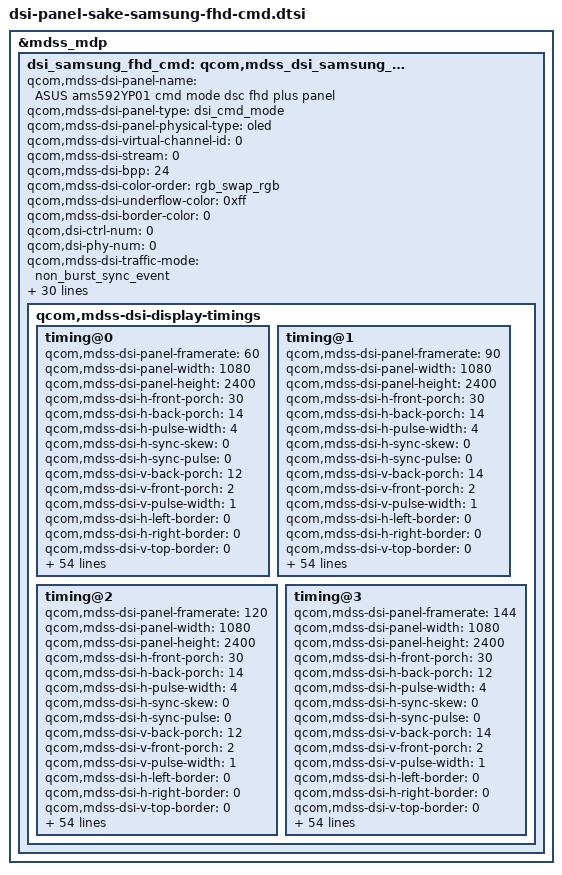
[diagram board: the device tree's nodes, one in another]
&mdss_mdp {
	dsi_samsung_fhd_cmd: qcom,mdss_dsi_samsung_fhd_cmd {
		qcom,mdss-dsi-panel-name = "ASUS ams592YP01 cmd mode dsc fhd plus panel";
		qcom,mdss-dsi-panel-type = "dsi_cmd_mode";
		qcom,mdss-dsi-panel-physical-type = "oled";
		qcom,mdss-dsi-virtual-channel-id = <0>;
		qcom,mdss-dsi-stream = <0>;
		qcom,mdss-dsi-bpp = <24>;
		qcom,mdss-dsi-color-order = "rgb_swap_rgb";
		qcom,mdss-dsi-underflow-color = <0xff>;
		qcom,mdss-dsi-border-color = <0>;

		qcom,dsi-ctrl-num = <0>;
		qcom,dsi-phy-num = <0>;

		qcom,mdss-dsi-traffic-mode = "non_burst_sync_event";
		qcom,mdss-dsi-lane-map = "lane_map_0123";
		qcom,mdss-dsi-bllp-eof-power-mode;
		qcom,mdss-dsi-bllp-power-mode;
		qcom,mdss-dsi-lane-0-state;
		qcom,mdss-dsi-lane-1-state;
		qcom,mdss-dsi-lane-2-state;
		qcom,mdss-dsi-lane-3-state;
		qcom,mdss-dsi-dma-trigger = "trigger_sw";
		qcom,mdss-dsi-mdp-trigger = "none";
		qcom,mdss-dsi-reset-sequence = <0 1>,<0 1>, <1 10>;
		qcom,mdss-dsi-te-pin-select = <1>;
		qcom,mdss-dsi-wr-mem-start = <0x2c>;
		qcom,mdss-dsi-wr-mem-continue = <0x3c>;
		qcom,mdss-dsi-te-dcs-command = <1>;
		qcom,mdss-dsi-te-check-enable;
		qcom,mdss-dsi-te-using-te-pin;
		qcom,mdss-pan-physical-width-dimension = <62>;
		qcom,mdss-pan-physical-height-dimension = <137>;
		qcom,mdss-dsi-panel-hdr-enabled;
		qcom,mdss-dsi-panel-hdr-color-primaries = <15635 16450 34000
			16000 13250 34500 7500 3000>;
		qcom,mdss-dsi-panel-peak-brightness = <4500000>;
		qcom,mdss-dsi-panel-blackness-level = <5>;

		qcom,mdss-dsi-panel-vendor-id = "AMS592YP01";
		qcom,mdss-dsi-bl-inverted-dbv;
		qcom,dynamic-mode-switch-enabled;
		qcom,dynamic-mode-switch-type = "dynamic-resolution-switch-immediate";

		qcom,fod-dim-lut = <
			/* brightness, alpha */
			4	233
			8	229
			12	225
			16	221
			20	218
			24	215
			28	213
			32	209
			36	207
			40	205
			44	203
			48	200
			52	200
			56	199
			60	196
			64	194
			68	192
			72	191
			76	189
			80	187
			84	186
			88	184
			92	182
			96	182
			100	181
			104	180
			108	178
			112	178
			116	176
			120	176
			124	176
			128	174
			132	172
			136	172
			140	171
			144	169
			148	168
			152	168
			156	166
			160	165
			164	165
			168	163
			172	163
			176	161
			180	160
			184	159
			188	159
			192	158
			196	156
			200	156
			234	151
			266	144
			299	138
			332	138
			365	128
			398	124
			431	117
			464	113
			497	108
			529	104
			562	99
			595	96
			628	92
			661	89
			694	86
			727	82
			760	79
			792	76
			825	74
			858	71
			891	70
			924	65
			957	60
			990	58
			1023	53
		>;

		qcom,mdss-dsi-display-timings {
			timing@0{
				qcom,mdss-dsi-panel-framerate = <60>;
				qcom,mdss-dsi-panel-width = <1080>;
				qcom,mdss-dsi-panel-height = <2400>;
				qcom,mdss-dsi-h-front-porch = <30>;
				qcom,mdss-dsi-h-back-porch = <14>;
				qcom,mdss-dsi-h-pulse-width = <4>;
				qcom,mdss-dsi-h-sync-skew = <0>;
				qcom,mdss-dsi-h-sync-pulse = <0>;
				qcom,mdss-dsi-v-back-porch = <12>;
				qcom,mdss-dsi-v-front-porch = <2>;
				qcom,mdss-dsi-v-pulse-width = <1>;
				qcom,mdss-dsi-h-left-border = <0>;
				qcom,mdss-dsi-h-right-border = <0>;
				qcom,mdss-dsi-v-top-border = <0>;
				qcom,mdss-dsi-v-bottom-border = <0>;
				qcom,mdss-dsi-panel-jitter = <0x05 0xa>;
				qcom,mdss-dsi-panel-clockrate = <1100000000>;

				qcom,default-topology-index = <0>;
				qcom,display-topology = <0x02 0x02 0x01>;
				qcom,mdss-dsi-panel-phy-timings = [00 13 04 04 13 1f 04 04 04 02 04 00 10 09];

				qcom,mdss-dsi-on-command = [05 01 00 00 0a 00 02 11 00 39 01 00 00 00 00 81 9e 11 00 00 89 30 80 09 60 04 38 00 28 02 1c 02 1c 02 00 02 0e 00 20 03 dd 00 07 00 0c 02 77 02 8b 18 00 10 f0 03 0c 20 00 06 0b 0b 33 0e 1c 2a 38 46 54 62 69 70 77 79 7b 7d 7e 01 02 01 00 09 40 09 be 19 fc 19 fa 19 f8 1a 38 1a 78 1a b6 2a f6 2b 34 2b 74 3b 74 6b f4 00 00 00 00 00 00 00 00 00 00 00 00 00 00 00 00 00 00 00 00 00 00 00 00 00 00 00 00 00 00 00 00 00 00 00 00 00 00 00 00 15 01 00 00 00 00 02 c2 14 15 01 00 00 00 00 02 9d 01 15 01 00 00 0a 00 02 35 00 39 01 00 00 00 00 05 2a 00 00 04 37 39 01 00 00 00 00 05 2b 00 00 09 5f 39 01 00 00 00 00 03 f0 5a 5a 39 01 00 00 00 00 03 b0 27 f2 15 01 00 00 00 00 02 f2 00 39 01 00 00 00 00 03 f0 a5 a5 39 01 00 00 00 00 03 f0 5a 5a 39 01 00 00 00 00 03 fc 5a 5a 15 01 00 00 00 00 02 c5 00 39 01 00 00 00 00 03 f0 a5 a5 39 01 00 00 00 00 03 fc a5 a5 39 01 00 00 00 00 03 f0 5a 5a 39 01 00 00 00 00 03 60 08 00 15 01 00 00 00 00 02 f7 0f 39 01 00 00 00 00 03 f0 a5 a5 39 01 00 00 00 00 03 f0 5a 5a 39 01 00 00 00 00 03 b0 09 f2 39 01 00 00 00 00 03 f2 26 f8 39 01 00 00 00 00 03 f0 a5 a5 39 01 00 00 00 00 03 f0 5a 5a 39 01 00 00 00 00 03 b0 2e f2 15 01 00 00 00 00 02 f2 55 15 01 00 00 00 00 02 f7 0f 39 01 00 00 00 00 03 f0 a5 a5 39 01 00 00 00 00 03 f0 5a 5a 39 01 00 00 00 00 03 b0 91 63 15 01 00 00 00 00 02 63 14 15 01 00 00 00 00 02 53 20 39 01 00 00 00 00 03 51 00 00 39 01 00 00 00 00 03 f0 a5 a5 15 01 00 00 00 00 02 53 28 15 01 00 00 00 00 02 55 00 05 01 00 00 00 00 02 29 00 39 01 00 00 00 00 03 f0 5a 5a 39 01 00 00 00 00 03 60 00 00 15 01 00 00 00 00 02 f7 0f 39 01 00 00 00 00 03 f0 a5 a5];

				qcom,mdss-dsi-off-command = [
					05 01 00 00 0A 00 02 28 00
					05 01 00 00 78 00 02 10 00
				];

				qcom,mdss-dsi-timing-switch-command = <0x39010000 0x3f0 0x5a5a3901 0x00 0x3fc5a5a 0x15010000 0x2c5 0x390100 0x03 0xf0a5a539 0x1000000 0x3fca5 0xa5390100 0x03 0xf05a5a39 0x1000000 0x36008 0x150100 0x02 0xf70f3901 0x00 0x3f0a5a5 0x39010000 0x3f0 0x5a5a3901 0x00 0x3b009f2 0x39010000 0x3f2 0x26f83901 0x00 0x3f0a5a5 0x39010000 0x3f0 0x5a5a3901 0x00 0x3600000 0x15010000 0x2f7 0xf390100 0x03 0xf0a5a515 0x1000000 0x25500>;

				qcom,mdss-dsi-fod-hbm-on-command = [
					// ELVSS DIM OFF & DLY OFF
					39 01 00 00 1C 00 03 F0 5A 5A
					39 01 00 00 00 00 03 B0 91 63
					15 01 00 00 00 00 02 63 50
					39 01 00 00 00 00 03 F0 A5 A5
					// HBM ON
					15 01 00 00 00 00 02 53 E0
					39 01 00 00 00 00 03 51 07 1C
				];

				qcom,mdss-dsi-fod-hbm-off-command = [
					// HBM OFF
					15 01 00 00 00 00 02 53 20
					// ELVSS DIM ON & DLY ON
					39 01 00 00 00 00 03 F0 5A 5A
					39 01 00 00 00 00 03 B0 91 63
					15 01 00 00 00 00 02 63 50
					39 01 00 00 00 00 03 F0 A5 A5
				];

				qcom,mdss-dsi-lp1-command = [
					//5.4 Frequency Change  60-120Hz
					39 01 00 00 00 00 03 F0 5A 5A
					39 01 00 00 00 00 03 60 08 00
					15 01 00 00 00 00 02 F7 0F
					39 01 00 00 00 00 03 F0 A5 A5
					05 01 00 00 10 00 02 28 00
				];

				qcom,mdss-dsi-nolp-command = [
					//4.2 AOD Mode OFF Setting
					39 01 00 00 00 00 03 F0 5A 5A
					15 01 00 00 00 00 02 53 20
					15 01 00 00 00 00 02 91 02
					39 01 00 00 00 00 03 F0 A5 A5
					05 01 00 00 00 00 02 29 00
					//5.4 Frequency Change  120-60Hz
					39 01 00 00 00 00 03 F0 5A 5A
					39 01 00 00 00 00 03 60 00 00
					15 01 00 00 00 00 02 F7 0F
					39 01 00 00 00 00 03 F0 A5 A5
				];

				qcom,mdss-dsi-aod-high-command = [
					// 24 for 40 nit
					39 01 00 00 00 00 03 F0 5A 5A
					15 01 00 00 00 00 02 91 01
					15 01 00 00 10 00 02 53 24
					39 01 00 00 00 00 03 F0 A5 A5
					05 01 00 00 00 00 02 29 00
				];

				qcom,mdss-dsi-aod-low-command = [
					// 25 for Low Mode
					39 01 00 00 00 00 03 F0 5A 5A
					15 01 00 00 00 00 02 91 01
					15 01 00 00 10 00 02 53 25
					39 01 00 00 00 00 03 F0 A5 A5
					05 01 00 00 00 00 02 29 00
				];

				qcom,mdss-dsi-aod-other-command = [
					05 01 00 00 00 00 02 29 00
				];

				qcom,mdss-dsi-aod-off-command = [
					05 01 00 00 10 00 02 28 00
				];

				qcom,mdss-dsi-on-command-state = "dsi_lp_mode";
				qcom,mdss-dsi-off-command-state = "dsi_hs_mode";
				qcom,mdss-dsi-timing-switch-command-state = "dsi_hs_mode";
				qcom,mdss-dsi-fod-hbm-on-command-state = "dsi_hs_mode";
				qcom,mdss-dsi-fod-hbm-off-command-state = "dsi_hs_mode";
				qcom,mdss-dsi-lp1-command-state = "dsi_hs_mode";
				qcom,mdss-dsi-nolp-command-state = "dsi_hs_mode";
				qcom,mdss-dsi-aod-high-command-state = "dsi_hs_mode";
				qcom,mdss-dsi-aod-low-command-state = "dsi_hs_mode";
				qcom,mdss-dsi-aod-other-command-state = "dsi_hs_mode";
				qcom,mdss-dsi-aod-off-command-state = "dsi_hs_mode";


				/* DSC */
				qcom,compression-mode = "dsc";
				qcom,mdss-dsc-slice-height = <40>;
				qcom,mdss-dsc-slice-width = <540>;
				qcom,mdss-dsc-slice-per-pkt = <1>;
				qcom,mdss-dsc-bit-per-component = <8>;
				qcom,mdss-dsc-bit-per-pixel = <8>;
				qcom,mdss-dsc-block-prediction-enable;
			};

			timing@1{
				qcom,mdss-dsi-panel-framerate = <90>;
				qcom,mdss-dsi-panel-width = <1080>;
				qcom,mdss-dsi-panel-height = <2400>;
				qcom,mdss-dsi-h-front-porch = <30>;
				qcom,mdss-dsi-h-back-porch = <14>;
				qcom,mdss-dsi-h-pulse-width = <4>;
				qcom,mdss-dsi-h-sync-skew = <0>;
				qcom,mdss-dsi-h-sync-pulse = <0>;
				qcom,mdss-dsi-v-back-porch = <14>;
				qcom,mdss-dsi-v-front-porch = <2>;
				qcom,mdss-dsi-v-pulse-width = <1>;
				qcom,mdss-dsi-h-left-border = <0>;
				qcom,mdss-dsi-h-right-border = <0>;
				qcom,mdss-dsi-v-top-border = <0>;
				qcom,mdss-dsi-v-bottom-border = <0>;
				qcom,mdss-dsi-panel-jitter = <0x05 0xa>;
				qcom,mdss-dsi-panel-clockrate = <1100000000>;

				qcom,default-topology-index = <0>;
				qcom,display-topology = <0x02 0x02 0x01>;
				qcom,mdss-dsi-panel-phy-timings = [00 13 04 04 13 1f 04 04 04 02 04 00 10 09];

				qcom,mdss-dsi-on-command = <0x5010000 0xa000211 0x390100 0x81 0x9e110000 0x89308009 0x60043800 0x28021c02 0x1c020002 0xe002003 0xdd000700 0xc027702 0x8b180010 0xf0030c20 0x60b0b 0x330e1c2a 0x38465462 0x69707779 0x7b7d7e01 0x2010009 0x4009be19 0xfc19fa19 0xf81a381a 0x781ab62a 0xf62b342b 0x743b746b 0xf4000000 0x00 0x00 0x00 0x00 0x00 0x00 0x00 0x00 0x00 0x150100 0x02 0xc2141501 0x00 0x29d0115 0x100000a 0x23500 0x39010000 0x52a 0x437 0x39010000 0x52b 0x95f 0x39010000 0x3f0 0x5a5a3901 0x00 0x3b027f2 0x15010000 0x2f2 0x390100 0x03 0xf0a5a539 0x1000000 0x3f05a 0x5a390100 0x03 0xfc5a5a15 0x1000000 0x2c500 0x39010000 0x3f0 0xa5a53901 0x00 0x3fca5a5 0x39010000 0x3f0 0x5a5a3901 0x00 0x3600800 0x15010000 0x2f7 0xf390100 0x03 0xf0a5a539 0x1000000 0x3f05a 0x5a390100 0x03 0xb009f239 0x1000000 0x3f226 0xf8390100 0x03 0xf0a5a539 0x1000000 0x3f05a 0x5a390100 0x03 0xb02ef215 0x1000000 0x2f255 0x15010000 0x2f7 0xf390100 0x03 0xf0a5a539 0x1000000 0x3f05a 0x5a390100 0x03 0xb0916315 0x1000000 0x26314 0x15010000 0x253 0x20390100 0x03 0x51000039 0x1000000 0x3f0a5 0xa5150100 0x02 0x53281501 0x00 0x2550005 0x1000000 0x22900 0x39010000 0x3f0 0x5a5a3901 0x00 0x3b009f2 0x39010000 0x3f2 0x33a83901 0x00 0x3f0a5a5>;

				qcom,mdss-dsi-off-command = [
					05 01 00 00 0A 00 02 28 00
					05 01 00 00 78 00 02 10 00
				];

				qcom,mdss-dsi-timing-switch-command = [39 01 00 00 00 00 03 f0 5a 5a 39 01 00 00 00 00 03 fc 5a 5a 15 01 00 00 00 00 02 c5 00 39 01 00 00 00 00 03 f0 a5 a5 39 01 00 00 00 00 03 fc a5 a5 39 01 00 00 00 00 03 f0 5a 5a 39 01 00 00 00 00 03 60 08 00 15 01 00 00 00 00 02 f7 0f 39 01 00 00 00 00 03 f0 a5 a5 39 01 00 00 00 00 03 f0 5a 5a 39 01 00 00 00 00 03 b0 09 f2 39 01 00 00 00 00 03 f2 33 a8 39 01 00 00 00 00 03 f0 a5 a5 15 01 00 00 00 00 02 55 00];

				qcom,mdss-dsi-fod-hbm-on-command = [
					// ELVSS DIM OFF & DLY OFF
					39 01 00 00 00 00 03 F0 5A 5A
					39 01 00 00 00 00 03 B0 91 63
					15 01 00 00 00 00 02 63 50
					39 01 00 00 00 00 03 F0 A5 A5
					// HBM ON
					15 01 00 00 00 00 02 53 E0
					39 01 00 00 00 00 03 51 07 1C
				];

				qcom,mdss-dsi-fod-hbm-off-command = [
					// HBM OFF
					15 01 00 00 00 00 02 53 20
					// ELVSS DIM ON & DLY ON
					39 01 00 00 00 00 03 F0 5A 5A
					39 01 00 00 00 00 03 B0 91 63
					15 01 00 00 00 00 02 63 50
					39 01 00 00 00 00 03 F0 A5 A5
				];

				qcom,mdss-dsi-lp1-command = [
					//7 Frequency Setting  90-120Hz
					39 01 00 00 00 00 03 F0 5A 5A
					39 01 00 00 00 00 03 B0 09 F2
					39 01 00 00 00 00 03 F2 26 F8
					39 01 00 00 00 00 03 F0 A5 A5
					05 01 00 00 10 00 02 28 00
				];

				qcom,mdss-dsi-nolp-command = [
					//4.2 AOD Mode OFF Setting
					39 01 00 00 00 00 03 F0 5A 5A
					15 01 00 00 00 00 02 53 20
					15 01 00 00 00 00 02 91 02
					39 01 00 00 00 00 03 F0 A5 A5
					05 01 00 00 00 00 02 29 00
					//5.4 Frequency Change  120-90Hz
					39 01 00 00 00 00 03 F0 5A 5A
					39 01 00 00 00 00 03 B0 09 F2
					39 01 00 00 00 00 03 F2 33 A8
					39 01 00 00 00 00 03 F0 A5 A5
				];

				qcom,mdss-dsi-aod-high-command = [
					// 24 for 40 nit
					39 01 00 00 00 00 03 F0 5A 5A
					15 01 00 00 00 00 02 91 01
					15 01 00 00 10 00 02 53 24
					39 01 00 00 00 00 03 F0 A5 A5
					05 01 00 00 00 00 02 29 00
				];

				qcom,mdss-dsi-aod-low-command = [
					// 25 for Low Mode
					39 01 00 00 00 00 03 F0 5A 5A
					15 01 00 00 00 00 02 91 01
					15 01 00 00 10 00 02 53 25
					39 01 00 00 00 00 03 F0 A5 A5
					05 01 00 00 00 00 02 29 00
				];

				qcom,mdss-dsi-aod-other-command = [
					05 01 00 00 00 00 02 29 00
				];

				qcom,mdss-dsi-aod-off-command = [
					05 01 00 00 10 00 02 28 00
				];

				qcom,mdss-dsi-on-command-state = "dsi_lp_mode";
				qcom,mdss-dsi-off-command-state = "dsi_hs_mode";
				qcom,mdss-dsi-timing-switch-command-state = "dsi_hs_mode";
				qcom,mdss-dsi-fod-hbm-on-command-state = "dsi_hs_mode";
				qcom,mdss-dsi-fod-hbm-off-command-state = "dsi_hs_mode";
				qcom,mdss-dsi-lp1-command-state = "dsi_hs_mode";
				qcom,mdss-dsi-nolp-command-state = "dsi_hs_mode";
				qcom,mdss-dsi-aod-high-command-state = "dsi_hs_mode";
				qcom,mdss-dsi-aod-low-command-state = "dsi_hs_mode";
				qcom,mdss-dsi-aod-other-command-state = "dsi_hs_mode";
				qcom,mdss-dsi-aod-off-command-state = "dsi_hs_mode";

				/* DSC */
				qcom,compression-mode = "dsc";
				qcom,mdss-dsc-slice-height = <40>;
				qcom,mdss-dsc-slice-width = <540>;
				qcom,mdss-dsc-slice-per-pkt = <1>;
				qcom,mdss-dsc-bit-per-component = <8>;
				qcom,mdss-dsc-bit-per-pixel = <8>;
				qcom,mdss-dsc-block-prediction-enable;
			};

			timing@2{
				qcom,mdss-dsi-panel-framerate = <120>;
				qcom,mdss-dsi-panel-width = <1080>;
				qcom,mdss-dsi-panel-height = <2400>;
				qcom,mdss-dsi-h-front-porch = <30>;
				qcom,mdss-dsi-h-back-porch = <14>;
				qcom,mdss-dsi-h-pulse-width = <4>;
				qcom,mdss-dsi-h-sync-skew = <0>;
				qcom,mdss-dsi-h-sync-pulse = <0>;
				qcom,mdss-dsi-v-back-porch = <12>;
				qcom,mdss-dsi-v-front-porch = <2>;
				qcom,mdss-dsi-v-pulse-width = <1>;
				qcom,mdss-dsi-h-left-border = <0>;
				qcom,mdss-dsi-h-right-border = <0>;
				qcom,mdss-dsi-v-top-border = <0>;
				qcom,mdss-dsi-v-bottom-border = <0>;
				qcom,mdss-dsi-panel-jitter = <0x05 0xa>;
				qcom,mdss-dsi-panel-clockrate = <1100000000>;

				qcom,default-topology-index = <0>;
				qcom,display-topology = <0x02 0x02 0x01>;
				qcom,mdss-dsi-panel-phy-timings = [00 13 04 04 13 1f 04 04 04 02 04 00 10 09];

				qcom,mdss-dsi-on-command = <0x5010000 0xa000211 0x390100 0x81 0x9e110000 0x89308009 0x60043800 0x28021c02 0x1c020002 0xe002003 0xdd000700 0xc027702 0x8b180010 0xf0030c20 0x60b0b 0x330e1c2a 0x38465462 0x69707779 0x7b7d7e01 0x2010009 0x4009be19 0xfc19fa19 0xf81a381a 0x781ab62a 0xf62b342b 0x743b746b 0xf4000000 0x00 0x00 0x00 0x00 0x00 0x00 0x00 0x00 0x00 0x150100 0x02 0xc2141501 0x00 0x29d0115 0x100000a 0x23500 0x39010000 0x52a 0x437 0x39010000 0x52b 0x95f 0x39010000 0x3f0 0x5a5a3901 0x00 0x3b027f2 0x15010000 0x2f2 0x390100 0x03 0xf0a5a539 0x1000000 0x3f05a 0x5a390100 0x03 0xfc5a5a15 0x1000000 0x2c500 0x39010000 0x3f0 0xa5a53901 0x00 0x3fca5a5 0x39010000 0x3f0 0x5a5a3901 0x00 0x3600800 0x15010000 0x2f7 0xf390100 0x03 0xf0a5a539 0x1000000 0x3f05a 0x5a390100 0x03 0xb009f239 0x1000000 0x3f226 0xf8390100 0x03 0xf0a5a539 0x1000000 0x3f05a 0x5a390100 0x03 0xb02ef215 0x1000000 0x2f255 0x15010000 0x2f7 0xf390100 0x03 0xf0a5a539 0x1000000 0x3f05a 0x5a390100 0x03 0xb0916315 0x1000000 0x26314 0x15010000 0x253 0x20390100 0x03 0x51000039 0x1000000 0x3f0a5 0xa5150100 0x02 0x53281501 0x00 0x2550005 0x1000000 0x22900>;

				qcom,mdss-dsi-off-command = [
					05 01 00 00 0A 00 02 28 00
					05 01 00 00 78 00 02 10 00
				];

				qcom,mdss-dsi-timing-switch-command = <0x39010000 0x3f0 0x5a5a3901 0x00 0x3fc5a5a 0x15010000 0x2c5 0x390100 0x03 0xf0a5a539 0x1000000 0x3fca5 0xa5390100 0x03 0xf05a5a39 0x1000000 0x36008 0x150100 0x02 0xf70f3901 0x00 0x3f0a5a5 0x39010000 0x3f0 0x5a5a3901 0x00 0x3b009f2 0x39010000 0x3f2 0x26f83901 0x00 0x3f0a5a5 0x39010000 0x3f0 0x5a5a3901 0x00 0x3600800 0x15010000 0x2f7 0xf390100 0x03 0xf0a5a515 0x1000000 0x25500>;

				qcom,mdss-dsi-fod-hbm-on-command = [
					// ELVSS DIM OFF & DLY OFF
					39 01 00 00 00 00 03 F0 5A 5A
					39 01 00 00 00 00 03 B0 91 63
					15 01 00 00 00 00 02 63 50
					39 01 00 00 00 00 03 F0 A5 A5
					// HBM ON
					15 01 00 00 00 00 02 53 E0
					39 01 00 00 00 00 03 51 07 1C
				];

				qcom,mdss-dsi-fod-hbm-off-command = [
					// HBM OFF
					15 01 00 00 00 00 02 53 20
					// ELVSS DIM ON & DLY ON
					39 01 00 00 00 00 03 F0 5A 5A
					39 01 00 00 00 00 03 B0 91 63
					15 01 00 00 00 00 02 63 50
					39 01 00 00 00 00 03 F0 A5 A5
				];

				qcom,mdss-dsi-lp1-command = [
					05 01 00 00 10 00 02 28 00
				];

				qcom,mdss-dsi-nolp-command = [
					//4.2 AOD Mode OFF Setting
					39 01 00 00 00 00 03 F0 5A 5A
					15 01 00 00 00 00 02 53 20
					15 01 00 00 00 00 02 91 02
					39 01 00 00 00 00 03 F0 A5 A5
					05 01 00 00 00 00 02 29 00
				];

				qcom,mdss-dsi-aod-high-command = [
					// 24 for 40 nit
					39 01 00 00 00 00 03 F0 5A 5A
					15 01 00 00 00 00 02 91 01
					15 01 00 00 10 00 02 53 24
					39 01 00 00 00 00 03 F0 A5 A5
					05 01 00 00 00 00 02 29 00
				];

				qcom,mdss-dsi-aod-low-command = [
					// 25 for Low Mode
					39 01 00 00 00 00 03 F0 5A 5A
					15 01 00 00 00 00 02 91 01
					15 01 00 00 10 00 02 53 25
					39 01 00 00 00 00 03 F0 A5 A5
					05 01 00 00 00 00 02 29 00
				];

				qcom,mdss-dsi-aod-other-command = [
					05 01 00 00 00 00 02 29 00
				];

				qcom,mdss-dsi-aod-off-command = [
					05 01 00 00 10 00 02 28 00
				];

				qcom,mdss-dsi-on-command-state = "dsi_lp_mode";
				qcom,mdss-dsi-off-command-state = "dsi_hs_mode";
				qcom,mdss-dsi-timing-switch-command-state = "dsi_hs_mode";
				qcom,mdss-dsi-fod-hbm-on-command-state = "dsi_hs_mode";
				qcom,mdss-dsi-fod-hbm-off-command-state = "dsi_hs_mode";
				qcom,mdss-dsi-lp1-command-state = "dsi_hs_mode";
				qcom,mdss-dsi-nolp-command-state = "dsi_hs_mode";
				qcom,mdss-dsi-aod-high-command-state = "dsi_hs_mode";
				qcom,mdss-dsi-aod-low-command-state = "dsi_hs_mode";
				qcom,mdss-dsi-aod-other-command-state = "dsi_hs_mode";
				qcom,mdss-dsi-aod-off-command-state = "dsi_hs_mode";

				/* DSC */
				qcom,compression-mode = "dsc";
				qcom,mdss-dsc-slice-height = <40>;
				qcom,mdss-dsc-slice-width = <540>;
				qcom,mdss-dsc-slice-per-pkt = <1>;
				qcom,mdss-dsc-bit-per-component = <8>;
				qcom,mdss-dsc-bit-per-pixel = <8>;
				qcom,mdss-dsc-block-prediction-enable;
			};

			timing@3 {
				qcom,mdss-dsi-panel-framerate = <144>;
				qcom,mdss-dsi-panel-width = <1080>;
				qcom,mdss-dsi-panel-height = <2400>;
				qcom,mdss-dsi-h-front-porch = <30>;
				qcom,mdss-dsi-h-back-porch = <12>;
				qcom,mdss-dsi-h-pulse-width = <4>;
				qcom,mdss-dsi-h-sync-skew = <0>;
				qcom,mdss-dsi-h-sync-pulse = <0>;
				qcom,mdss-dsi-v-back-porch = <14>;
				qcom,mdss-dsi-v-front-porch = <2>;
				qcom,mdss-dsi-v-pulse-width = <1>;
				qcom,mdss-dsi-h-left-border = <0>;
				qcom,mdss-dsi-h-right-border = <0>;
				qcom,mdss-dsi-v-top-border = <0>;
				qcom,mdss-dsi-v-bottom-border = <0>;
				qcom,mdss-dsi-panel-jitter = <0x05 0xa>;
				qcom,mdss-dsi-panel-clockrate = <1100000000>;

				qcom,default-topology-index = <0>;
				qcom,display-topology = <0x02 0x02 0x01>;
				qcom,mdss-dsi-panel-phy-timings = [00 13 04 04 13 1f 04 04 04 02 04 00 10 09];

				qcom,mdss-dsi-timing-switch-command = [39 01 00 00 00 00 03 f0 5a 5a 39 01 00 00 00 00 03 60 08 00 15 01 00 00 00 00 02 f7 0f 39 01 00 00 00 00 03 f0 a5 a5 39 01 00 00 00 00 03 f0 5a 5a 39 01 00 00 00 00 03 fc 5a 5a 15 01 00 00 00 00 02 c5 0d 39 01 00 00 00 00 03 f0 a5 a5 39 01 00 00 00 00 03 fc a5 a5 39 01 00 00 00 00 03 f0 5a 5a 39 01 00 00 00 00 03 b0 09 f2 39 01 00 00 00 00 03 f2 22 7e 39 01 00 00 00 00 03 f0 a5 a5 15 01 00 00 00 00 02 55 03];

				qcom,mdss-dsi-off-command = [
					05 01 00 00 0A 00 02 28 00
					05 01 00 00 78 00 02 10 00
				];

				qcom,mdss-dsi-on-command = [05 01 00 00 0a 00 02 11 00 39 01 00 00 00 00 81 9e 11 00 00 89 30 80 09 60 04 38 00 28 02 1c 02 1c 02 00 02 0e 00 20 03 dd 00 07 00 0c 02 77 02 8b 18 00 10 f0 03 0c 20 00 06 0b 0b 33 0e 1c 2a 38 46 54 62 69 70 77 79 7b 7d 7e 01 02 01 00 09 40 09 be 19 fc 19 fa 19 f8 1a 38 1a 78 1a b6 2a f6 2b 34 2b 74 3b 74 6b f4 00 00 00 00 00 00 00 00 00 00 00 00 00 00 00 00 00 00 00 00 00 00 00 00 00 00 00 00 00 00 00 00 00 00 00 00 00 00 00 00 15 01 00 00 00 00 02 c2 14 15 01 00 00 00 00 02 9d 01 15 01 00 00 0a 00 02 35 00 39 01 00 00 00 00 05 2a 00 00 04 37 39 01 00 00 00 00 05 2b 00 00 09 5f 39 01 00 00 00 00 03 f0 5a 5a 39 01 00 00 00 00 03 b0 27 f2 15 01 00 00 00 00 02 f2 00 39 01 00 00 00 00 03 f0 a5 a5 39 01 00 00 00 00 03 f0 5a 5a 39 01 00 00 00 00 03 fc 5a 5a 15 01 00 00 00 00 02 c5 00 39 01 00 00 00 00 03 f0 a5 a5 39 01 00 00 00 00 03 fc a5 a5 39 01 00 00 00 00 03 f0 5a 5a 39 01 00 00 00 00 03 60 08 00 15 01 00 00 00 00 02 f7 0f 39 01 00 00 00 00 03 f0 a5 a5 39 01 00 00 00 00 03 f0 5a 5a 39 01 00 00 00 00 03 b0 09 f2 39 01 00 00 00 00 03 f2 26 f8 39 01 00 00 00 00 03 f0 a5 a5 39 01 00 00 00 00 03 f0 5a 5a 39 01 00 00 00 00 03 b0 2e f2 15 01 00 00 00 00 02 f2 55 15 01 00 00 00 00 02 f7 0f 39 01 00 00 00 00 03 f0 a5 a5 39 01 00 00 00 00 03 f0 5a 5a 39 01 00 00 00 00 03 b0 91 63 15 01 00 00 00 00 02 63 14 15 01 00 00 00 00 02 53 20 39 01 00 00 00 00 03 51 00 00 39 01 00 00 00 00 03 f0 a5 a5 15 01 00 00 00 00 02 53 28 15 01 00 00 00 00 02 55 03 05 01 00 00 00 00 02 29 00 39 01 00 00 00 00 03 f0 5a 5a 39 01 00 00 00 00 03 fc 5a 5a 15 01 00 00 00 00 02 c5 0d 39 01 00 00 00 00 03 f0 a5 a5 39 01 00 00 00 00 03 fc a5 a5 39 01 00 00 00 00 03 f0 5a 5a 39 01 00 00 00 00 03 b0 09 f2 39 01 00 00 00 00 03 f2 22 7e 39 01 00 00 00 00 03 f0 a5 a5];

				qcom,mdss-dsi-fod-hbm-on-command = [
					// ELVSS DIM OFF & DLY OFF
					39 01 00 00 00 00 03 F0 5A 5A
					39 01 00 00 00 00 03 B0 91 63
					15 01 00 00 00 00 02 63 50
					39 01 00 00 00 00 03 F0 A5 A5
					// HBM ON
					15 01 00 00 00 00 02 53 E0
					39 01 00 00 00 00 03 51 07 1C
				];
				qcom,mdss-dsi-fod-hbm-off-command = [
					// HBM OFF
					15 01 00 00 00 00 02 53 20
					// ELVSS DIM ON & DLY ON
					39 01 00 00 00 00 03 F0 5A 5A
					39 01 00 00 00 00 03 B0 91 63
					15 01 00 00 00 00 02 63 50
					39 01 00 00 00 00 03 F0 A5 A5
				];
				qcom,mdss-dsi-lp1-command = [
					05 01 00 00 10 00 02 28 00
				];
				qcom,mdss-dsi-nolp-command = [
					//4.2 AOD Mode OFF Setting
					39 01 00 00 00 00 03 F0 5A 5A
					15 01 00 00 00 00 02 53 20
					15 01 00 00 00 00 02 91 02
					39 01 00 00 00 00 03 F0 A5 A5
					05 01 00 00 00 00 02 29 00
				];
				qcom,mdss-dsi-aod-high-command = [
					// 24 for 40 nit
					39 01 00 00 00 00 03 F0 5A 5A
					15 01 00 00 00 00 02 91 01
					15 01 00 00 10 00 02 53 24
					39 01 00 00 00 00 03 F0 A5 A5
					05 01 00 00 00 00 02 29 00
				];
				qcom,mdss-dsi-aod-low-command = [
					// 25 for Low Mode
					39 01 00 00 00 00 03 F0 5A 5A
					15 01 00 00 00 00 02 91 01
					15 01 00 00 10 00 02 53 25
					39 01 00 00 00 00 03 F0 A5 A5
					05 01 00 00 00 00 02 29 00
				];
				qcom,mdss-dsi-aod-other-command = [
					05 01 00 00 00 00 02 29 00
				];
				qcom,mdss-dsi-aod-off-command = [
					05 01 00 00 10 00 02 28 00
				];

				qcom,mdss-dsi-on-command-state = "dsi_lp_mode";
				qcom,mdss-dsi-off-command-state = "dsi_hs_mode";
				qcom,mdss-dsi-timing-switch-command-state = "dsi_hs_mode";
				qcom,mdss-dsi-fod-hbm-on-command-state = "dsi_hs_mode";
				qcom,mdss-dsi-fod-hbm-off-command-state = "dsi_hs_mode";
				qcom,mdss-dsi-lp1-command-state = "dsi_hs_mode";
				qcom,mdss-dsi-nolp-command-state = "dsi_hs_mode";
				qcom,mdss-dsi-aod-high-command-state = "dsi_hs_mode";
				qcom,mdss-dsi-aod-low-command-state = "dsi_hs_mode";
				qcom,mdss-dsi-aod-other-command-state = "dsi_hs_mode";
				qcom,mdss-dsi-aod-off-command-state = "dsi_hs_mode";

				/* DSC */
				qcom,compression-mode = "dsc";
				qcom,mdss-dsc-slice-height = <40>;
				qcom,mdss-dsc-slice-width = <540>;
				qcom,mdss-dsc-slice-per-pkt = <1>;
				qcom,mdss-dsc-bit-per-component = <8>;
				qcom,mdss-dsc-bit-per-pixel = <8>;
				qcom,mdss-dsc-block-prediction-enable;
			};
		};
	};
};
